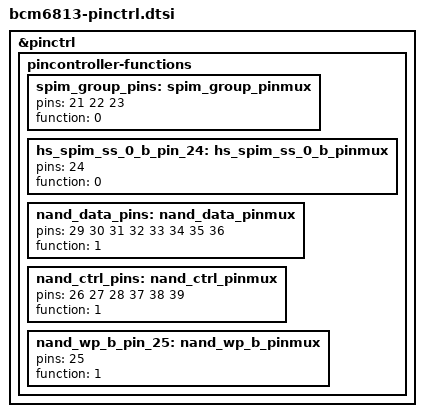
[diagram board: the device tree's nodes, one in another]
&pinctrl {
	pincontroller-functions {
		spim_group_pins: spim_group_pinmux {
			pins = <21 22 23>;
			function = <0>;
		};

		hs_spim_ss_0_b_pin_24: hs_spim_ss_0_b_pinmux {
			pins = <24>;
			function = <0>;
		};

		nand_data_pins: nand_data_pinmux {
			pins = <29 30 31 32 33 34 35 36>;
			function = <1>;
		};

		nand_ctrl_pins: nand_ctrl_pinmux {
			pins = <26 27 28 37 38 39>;
			function = <1>;
		};

		nand_wp_b_pin_25: nand_wp_b_pinmux {
			pins = <25>;
			function = <1>;
		};
	};
};
